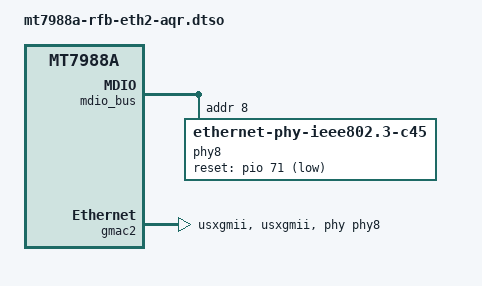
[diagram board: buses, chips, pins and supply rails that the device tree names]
// SPDX-License-Identifier: (GPL-2.0 OR MIT)
/*
 * Copyright (C) 2022 MediaTek Inc.
 * Author: Sam.Shih <sam.shih@mediatek.com>
 */

/dts-v1/;
/plugin/;

#include <dt-bindings/gpio/gpio.h>

/ {
	compatible = "mediatek,mt7988a-rfb", "mediatek,mt7988a";

	fragment@0 {
		target = <&mdio_bus>;
		__overlay__ {
			#address-cells = <1>;
			#size-cells = <0>;

			/* external Aquantia AQR113C */
			phy8: ethernet-phy@8 {
				reg = <8>;
				compatible = "ethernet-phy-ieee802.3-c45";
				firmware-name = "AQR-G4_v5.7.0-AQR_EVB_Generic_X3410_StdCfg_MDISwap_USX_ID46316_VER2140.cld";
				reset-gpios = <&pio 71 GPIO_ACTIVE_LOW>;
				reset-assert-us = <100000>;
				reset-deassert-us = <221000>;
			};
		};
	};

	fragment@1 {
		target = <&gmac2>;
		__overlay__ {
			phy-mode = "usxgmii";
			phy-connection-type = "usxgmii";
			phy = <&phy8>;
			status = "okay";
		};
	};
};
